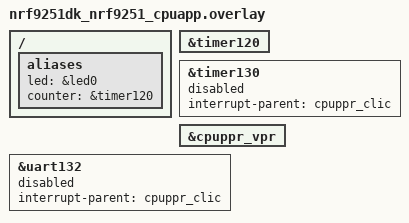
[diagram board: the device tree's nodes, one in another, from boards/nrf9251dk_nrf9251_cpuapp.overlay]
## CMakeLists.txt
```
#
# Copyright (c) 2025 Nordic Semiconductor ASA
#
# SPDX-License-Identifier: LicenseRef-Nordic-5-Clause
#

cmake_minimum_required(VERSION 3.20.0)

find_package(Zephyr REQUIRED HINTS $ENV{ZEPHYR_BASE})

if(NOT SYSBUILD)
  message(FATAL_ERROR
    " This is a multi-image application that should be built using sysbuild.\n"
    " Add --sysbuild argument to west build command to prepare all the images."
  )
endif()

project(idle_counter)

target_sources(app PRIVATE src/main.c)
```

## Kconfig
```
#
# Copyright (c) 2025 Nordic Semiconductor ASA
#
# SPDX-License-Identifier: LicenseRef-Nordic-5-Clause
#

config TEST_SLEEP_DURATION_MS
	int "Core sleep duration (miliseconds)"
	default 1000
	help
	  Set sleep duration to TEST_SLEEP_DURATION_MS miliseconds.
	  Based on the value of 'min-residency-us' specified for each power state
	  defined in the DTS, core enters the lowest possible power state.

config TEST_SLEEP_ERROR_MS
	int "Allowed error (miliseconds)"
	default 10
	help
	  Test will pass if actual Alarm arrives within
	  TEST_SLEEP_DURATION_MS +/- TEST_SLEEP_ERROR_MS.

source "Kconfig.zephyr"
```

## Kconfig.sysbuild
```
#
# Copyright (c) 2024 Nordic Semiconductor ASA
#
# SPDX-License-Identifier: LicenseRef-Nordic-5-Clause
#

if SUPPORT_NETCORE

choice NETCORE
	default NETCORE_REMOTE

config NETCORE_REMOTE
	bool "Remote image"

endchoice

config NETCORE_IMAGE_NAME
	default "remote" if NETCORE_REMOTE

config NETCORE_IMAGE_PATH
	default "$(ZEPHYR_NRF_MODULE_DIR)/tests/benchmarks/multicore/idle_counter/remote" if NETCORE_REMOTE

endif # SUPPORT_NETCORE

if SUPPORT_PPRCORE

choice PPRCORE
	default PPRCORE_REMOTE if SOC_NRF9251_CPUAPP
	default PPRCORE_NONE

config PPRCORE_REMOTE
	bool "Remote image"

endchoice

config PPRCORE_IMAGE_NAME
	default "remote_ppr" if PPRCORE_REMOTE

config PPRCORE_IMAGE_PATH
	default "$(ZEPHYR_NRF_MODULE_DIR)/tests/benchmarks/multicore/idle_counter/remote" if PPRCORE_REMOTE

endif # SUPPORT_PPRCORE

source "share/sysbuild/Kconfig"
```

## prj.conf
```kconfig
# Drivers and peripherals
CONFIG_COUNTER=y

# Enable runtime power management for peripheral
CONFIG_PM_DEVICE=y
CONFIG_PM_DEVICE_RUNTIME=y

CONFIG_PM=y
CONFIG_POWEROFF=y
CONFIG_CONSOLE=n
CONFIG_UART_CONSOLE=n
CONFIG_SERIAL=n
CONFIG_BOOT_BANNER=n
CONFIG_NCS_BOOT_BANNER=n
CONFIG_LOG=n

CONFIG_ASSERT=y
```

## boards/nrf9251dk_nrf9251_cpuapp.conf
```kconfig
#
# Copyright (c) 2026 Nordic Semiconductor ASA
#
# SPDX-License-Identifier: LicenseRef-Nordic-5-Clause
#

# Icrease tolerance due to missing trims
CONFIG_TEST_SLEEP_ERROR_MS=15
```

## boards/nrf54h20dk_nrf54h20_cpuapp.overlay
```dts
/*
 * Copyright (c) 2025 Nordic Semiconductor ASA
 *
 * SPDX-License-Identifier: LicenseRef-Nordic-5-Clause
 */

/ {
	aliases {
		led = &led0;
		/delete-property/ led1;
		counter = &timer120;
	};
};

&timer120 {
	status = "okay";
};

/delete-node/ &led1;

&hsfll120 {
	status = "okay";
};
```

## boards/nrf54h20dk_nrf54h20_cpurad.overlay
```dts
/*
 * Copyright (c) 2025 Nordic Semiconductor ASA
 *
 * SPDX-License-Identifier: LicenseRef-Nordic-5-Clause
 */

&hsfll120 {
	status = "okay";
};
```

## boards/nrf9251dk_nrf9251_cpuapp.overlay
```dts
/*
 * Copyright (c) 2026 Nordic Semiconductor ASA
 *
 * SPDX-License-Identifier: LicenseRef-Nordic-5-Clause
 */

/ {
	aliases {
		led = &led0;
		counter = &timer120;
	};
};

&timer120 {
	status = "okay";
};

&timer130 {
	status = "reserved";
	interrupt-parent = <&cpuppr_clic>;
};

&cpuppr_vpr {
	status = "okay";
};

&uart132 {
	status = "reserved";
	interrupt-parent = <&cpuppr_clic>;
};
```

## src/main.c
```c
/*
 * Copyright (c) 2025 Nordic Semiconductor ASA
 *
 * SPDX-License-Identifier: LicenseRef-Nordic-5-Clause
 */

#include <zephyr/kernel.h>
#include <zephyr/cache.h>
#include <zephyr/drivers/gpio.h>
#include <zephyr/drivers/counter.h>
#include <zephyr/logging/log.h>

LOG_MODULE_REGISTER(idle_counter);

#if defined(SOC_NRF54H20)
#define SHM_START_ADDR (DT_REG_ADDR(DT_NODELABEL(cpuapp_cpurad_ipc_shm)))
#else
#define SHM_START_ADDR (DT_REG_ADDR(DT_NODELABEL(cpuapp_cpuppr_ipc_shm)))
#endif
volatile static uint32_t *shared_var = (volatile uint32_t *)SHM_START_ADDR;
#define HOST_IS_READY	(1)
#define REMOTE_IS_READY (2)

static const struct gpio_dt_spec led = GPIO_DT_SPEC_GET(DT_ALIAS(led), gpios);

#define ALARM_CHANNEL_ID (0)
const struct device *const counter_dev = DEVICE_DT_GET(DT_ALIAS(counter));

static K_SEM_DEFINE(my_sem, 0, 1);

#define ALLOWED_SLEEP_MIN (CONFIG_TEST_SLEEP_DURATION_MS - CONFIG_TEST_SLEEP_ERROR_MS)
#define ALLOWED_SLEEP_MAX (CONFIG_TEST_SLEEP_DURATION_MS + CONFIG_TEST_SLEEP_ERROR_MS)

void counter_handler(const struct device *counter_dev, uint8_t chan_id, uint32_t ticks,
		     void *user_data)
{
	k_sem_give(&my_sem);
	counter_stop(counter_dev);
}

uint32_t start_timer(const struct device *counter_dev)
{
	uint32_t start_time;
	struct counter_alarm_cfg counter_cfg;

	counter_cfg.flags = 0;
	counter_cfg.ticks = counter_us_to_ticks(counter_dev, CONFIG_TEST_SLEEP_DURATION_MS * 1000);
	counter_cfg.callback = counter_handler;
	counter_cfg.user_data = &counter_cfg;
	counter_set_channel_alarm(counter_dev, ALARM_CHANNEL_ID, &counter_cfg);

	counter_start(counter_dev);
	start_time = k_cycle_get_32();

	LOG_INF("Counter starts at %u cycle", start_time);

	return start_time;
}

void verify_timer(uint32_t start_time)
{
	uint32_t elapsed;
	int ret;

	ret = gpio_pin_set_dt(&led, 0);
	__ASSERT(ret == 0, "Unable to turn off LED");
	ret = k_sem_take(&my_sem, K_MSEC(CONFIG_TEST_SLEEP_DURATION_MS + 100));
	elapsed = k_cycle_get_32() - start_time;
	__ASSERT(ret == 0, "Timer callback not called");
	ret = gpio_pin_set_dt(&led, 1);
	__ASSERT(ret == 0, "Unable to turn on LED");
	LOG_INF("Elapsed %u cycles (%uus)", elapsed, k_cyc_to_us_ceil32(elapsed));
	__ASSERT(elapsed > k_ms_to_cyc_ceil32(ALLOWED_SLEEP_MIN) &&
		 elapsed < k_ms_to_cyc_ceil32(ALLOWED_SLEEP_MAX),
		 "expected time to elapse is 1s");
}

void sleep_with_state_indication(uint32_t sleep_duration_ms)
{
	int ret;

	ret = gpio_pin_set_dt(&led, 0);
	__ASSERT(ret == 0, "Unable to turn off LED");
	k_msleep(sleep_duration_ms);
	ret = gpio_pin_set_dt(&led, 1);
	__ASSERT(ret == 0, "Unable to turn on LED");
}

int main(void)
{
	uint32_t start_time;
	int ret;

	ret = gpio_is_ready_dt(&led);
	__ASSERT(ret, "Error: GPIO Device not ready");

	ret = gpio_pin_configure_dt(&led, GPIO_OUTPUT_ACTIVE);
	__ASSERT(ret == 0, "Could not configure led GPIO");

	/* Wait a bit to solve NRFS request timeout issue. */
	k_msleep(1000);

	/* Synchronize Remote core with Host core */
#if !defined(CONFIG_TEST_ROLE_REMOTE)
	LOG_DBG("HOST starts");
	*shared_var = HOST_IS_READY;
	sys_cache_data_flush_range((void *)shared_var, sizeof(*shared_var));
	LOG_DBG("HOST wrote HOST_IS_READY: %u", *shared_var);
	while (*shared_var != REMOTE_IS_READY) {
		sys_cache_data_invd_range((void *)shared_var, sizeof(*shared_var));
		LOG_DBG("shared_var is: %u", *shared_var);
	}
	LOG_DBG("HOST continues");
#else
	LOG_DBG("REMOTE starts");
	while (*shared_var != HOST_IS_READY) {
		sys_cache_data_invd_range((void *)shared_var, sizeof(*shared_var));
		LOG_DBG("shared_var is: %u", *shared_var);
	}
	LOG_DBG("REMOTE found that HOST_IS_READY");
	*shared_var = REMOTE_IS_READY;
	sys_cache_data_flush_range((void *)shared_var, sizeof(*shared_var));
	LOG_DBG("REMOTE wrote REMOTE_IS_READY: %u", *shared_var);
	LOG_DBG("REMOTE continues");
#endif

	while (1) {
		sleep_with_state_indication(CONFIG_TEST_SLEEP_DURATION_MS);
		start_time = start_timer(counter_dev);
		k_msleep(100);
		verify_timer(start_time);
		k_busy_wait(100000);
	}

	return 0;
}
```
